# CM_WKUP register map
Vendor: Texas Instruments
Peripheral module from a debugger description file (folder am335x).
Registers are 32-bit, access per field, no defined reset value unless marked. A register's access mark holds for its fields unless they carry their own. Offsets are as the file gives them; lines under a group give offsets from that group; [hi:lo] are bit positions; {n}, {i} and the like mark numbered series; 'fields as' and 'values as' point back to an identical list; <NAME> marks a mode.

## CM_WKUP
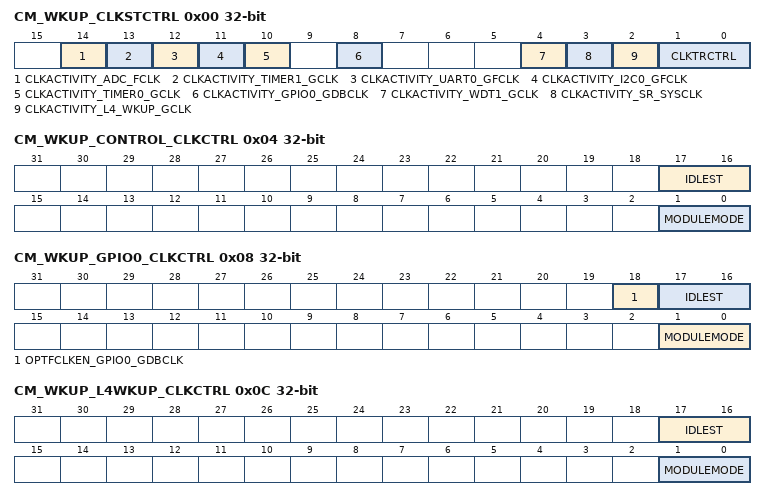
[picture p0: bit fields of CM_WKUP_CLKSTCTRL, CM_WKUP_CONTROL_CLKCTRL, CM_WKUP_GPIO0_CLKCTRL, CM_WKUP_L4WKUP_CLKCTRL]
0x00 CM_WKUP_CLKSTCTRL — This register enables the domain power state transition. It controls the SW supervised clock domain state transition between ON-ACTIVE and ON-INACTIVE states. It also hold one status bit per clock input of the domain.
  [14] CLKACTIVITY_ADC_FCLK ro — This field indicates the state of the ADC clock in the domain.
    0=Inact (Corresponding clock is gated); 1=Act (Corresponding clock is active)
  [13] CLKACTIVITY_TIMER1_GCLK ro — This field indicates the state of the TIMER1 clock in the domain.
    values as CLKACTIVITY_ADC_FCLK
  [12] CLKACTIVITY_UART0_GFCLK ro — This field indicates the state of the UART0 clock in the domain.
    values as CLKACTIVITY_ADC_FCLK
  [11] CLKACTIVITY_I2C0_GFCLK ro — This field indicates the state of the I2C0 clock in the domain.
    values as CLKACTIVITY_ADC_FCLK
  [10] CLKACTIVITY_TIMER0_GCLK ro — This field indicates the state of the WKUPTIMER_GCLK clock in the domain.
    values as CLKACTIVITY_ADC_FCLK
  [8] CLKACTIVITY_GPIO0_GDBCLK ro — This field indicates the state of the WKUPGPIO_DBGICLK clock in the domain.
    values as CLKACTIVITY_ADC_FCLK
  [4] CLKACTIVITY_WDT1_GCLK ro — This field indicates the state of the WDT1_GCLK clock in the domain.
    values as CLKACTIVITY_ADC_FCLK
  [3] CLKACTIVITY_SR_SYSCLK ro — This field indicates the state of the SMARTREFGLEX SYSCLK clock in the domain.
    values as CLKACTIVITY_ADC_FCLK
  [2] CLKACTIVITY_L4_WKUP_GCLK ro — This field indicates the state of the L4_WKUP clock in the domain.
    values as CLKACTIVITY_ADC_FCLK
  [1:0] CLKTRCTRL rw — Controls the clock state transition of the always on clock domain.
    0=NO_SLEEP (NO_SLEEP: Sleep transition cannot be initiated. Wakeup transition may however occur.); 1=SW_SLEEP (SW_SLEEP: Start a software forced sleep transition on the domain.); 2=SW_WKUP (SW_WKUP: Start a software forced wake-up transition on the domain.)
0x04 CM_WKUP_CONTROL_CLKCTRL — This register manages the Control Module clocks.
  [17:16] IDLEST ro — Module idle status.
    0=Func (Module is fully functional, including OCP); 1=Trans (Module is performing transition: wakeup, or sleep, or sleep abortion); 2=Idle (Module is in Idle mode (only OCP part). It is functional if using separate functional clock); 3=Disable (Module is disabled and cannot be accessed)
  [1:0] MODULEMODE rw — Control the way mandatory clocks are managed.
    0=DISABLED (Module is disable by SW. Any OCP access to module results in an error, except if resulting from a module wakeup (asynchronous wakeup).); 2=ENABLE (Module is explicitly enabled. Interface clock (if not used for functions) may be gated according to the clock domain state. Functional clocks are guarantied to stay present. As long as in this configuration, power domain sleep transition cannot happen.)
0x08 CM_WKUP_GPIO0_CLKCTRL — This register manages the GPIO0 clocks.
  [18] OPTFCLKEN_GPIO0_GDBCLK rw — Optional functional clock control.
    0=FCLK_DIS (Optional functional clock is disabled); 1=FCLK_EN (Optional functional clock is enabled)
  [17:16] IDLEST ro — Module idle status.
    values as CM_WKUP_CONTROL_CLKCTRL.IDLEST
  [1:0] MODULEMODE rw — Control the way mandatory clocks are managed.
    values as CM_WKUP_CONTROL_CLKCTRL.MODULEMODE
0x0C CM_WKUP_L4WKUP_CLKCTRL ro — This register manages the L4WKUP clocks.
  [17:16] IDLEST — Module idle status.
    values as CM_WKUP_CONTROL_CLKCTRL.IDLEST
  [1:0] MODULEMODE — Control the way mandatory clocks are managed.
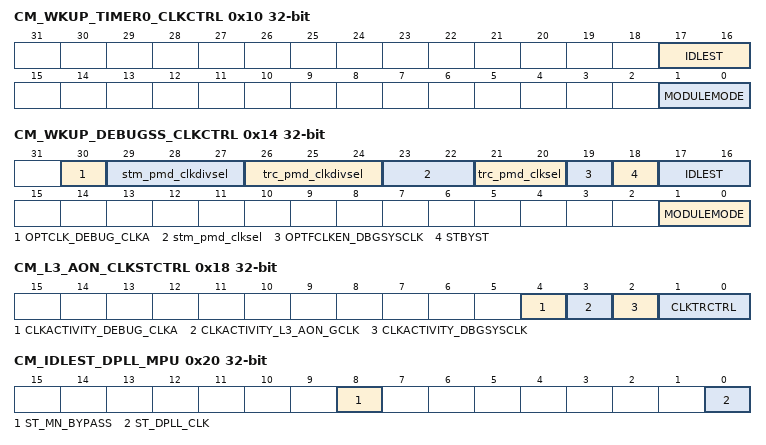
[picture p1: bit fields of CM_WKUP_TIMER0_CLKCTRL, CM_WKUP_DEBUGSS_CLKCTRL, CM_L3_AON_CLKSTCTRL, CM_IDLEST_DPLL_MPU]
0x10 CM_WKUP_TIMER0_CLKCTRL — This register manages the TIMER0 clocks.
  fields as CM_WKUP_CONTROL_CLKCTRL
0x14 CM_WKUP_DEBUGSS_CLKCTRL — This register manages the DEBUGSS clocks.
  [30] OPTCLK_DEBUG_CLKA rw
  [29:27] stm_pmd_clkdivsel rw
  [26:24] trc_pmd_clkdivsel rw
  [23:22] stm_pmd_clksel rw
  [21:20] trc_pmd_clksel rw
  [19] OPTFCLKEN_DBGSYSCLK rw — Optional functional clock control.
    values as CM_WKUP_GPIO0_CLKCTRL.OPTFCLKEN_GPIO0_GDBCLK
  [18] STBYST ro — Module standby status.
    0=Func (Module is functional (not in standby)); 1=Standby (Module is in standby)
  [17:16] IDLEST ro — Module idle status.
    values as CM_WKUP_CONTROL_CLKCTRL.IDLEST
  [1:0] MODULEMODE rw — Control the way mandatory clocks are managed.
    values as CM_WKUP_CONTROL_CLKCTRL.MODULEMODE
0x18 CM_L3_AON_CLKSTCTRL — This register enables the domain power state transition. It controls the SW supervised clock domain state transition between ON-ACTIVE and ON-INACTIVE states. It also hold one status bit per clock input of the domain.
  [4] CLKACTIVITY_DEBUG_CLKA ro — This field indicates the state of the Debugss CLKA clock in the domain.
  [3] CLKACTIVITY_L3_AON_GCLK ro — This field indicates the state of the L3_AON clock in the domain.
    values as CM_WKUP_CLKSTCTRL.CLKACTIVITY_ADC_FCLK
  [2] CLKACTIVITY_DBGSYSCLK ro — This field indicates the state of the Debugss sysclk clock in the domain.
    values as CM_WKUP_CLKSTCTRL.CLKACTIVITY_ADC_FCLK
  [1:0] CLKTRCTRL rw — Controls the clock state transition of the L3 AON clock domain.
    values as CM_WKUP_CLKSTCTRL.CLKTRCTRL
0x1C CM_AUTOIDLE_DPLL_MPU — This register provides automatic control over the DPLL activity.
  [2:0] AUTO_DPLL_MODE rw — This feature is not supported.
0x20 CM_IDLEST_DPLL_MPU ro — This register allows monitoring the master clock activity. This register is read only and automatically updated.[warm reset insensitive]
  [8] ST_MN_BYPASS — DPLL MN_BYPASS status
    0=NO_MNBYPASS (DPLL is not in MN_Bypass); 1=MN_BYPASS (DPLL is in MN_Bypass)
  [0] ST_DPLL_CLK — DPLL clock activity
    0=DPLL_UNLOCKED (DPLL is either in bypass mode or in stop mode.); 1=DPLL_LOCKED (DPLL is LOCKED)
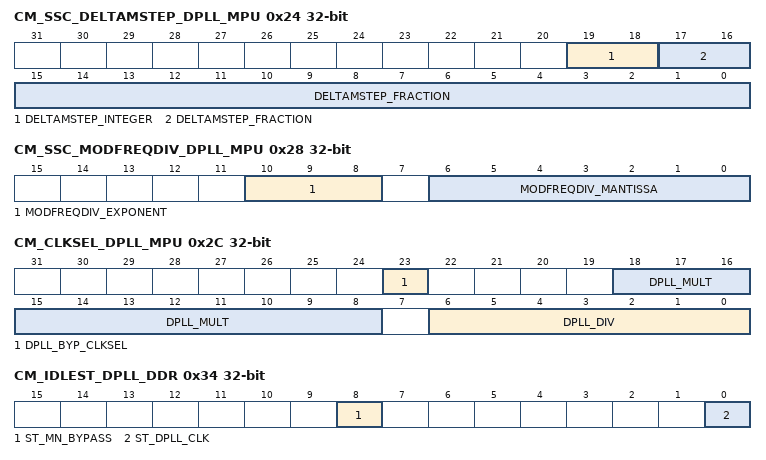
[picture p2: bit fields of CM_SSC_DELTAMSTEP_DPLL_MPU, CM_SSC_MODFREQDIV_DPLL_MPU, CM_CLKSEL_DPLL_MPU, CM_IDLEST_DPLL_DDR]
0x24 CM_SSC_DELTAMSTEP_DPLL_MPU — Control the DeltaMStep parameter for Spread Spectrum Clocking technique DeltaMStep is split into fractional and integer part. [warm reset insensitive]
  [19:18] DELTAMSTEP_INTEGER rw — Integer part for DeltaM coefficient
  [17:0] DELTAMSTEP_FRACTION rw — Fractional part for DeltaM coefficient
0x28 CM_SSC_MODFREQDIV_DPLL_MPU — Control the Modulation Frequency (Fm) for Spread Spectrum Clocking technique by defining it as a ratio of DPLL_REFCLK/4 Fm = [DPLL_REFCLK/4]/MODFREQDIV MODFREQDIV = MODFREQDIV_MANTISSA * 2^MODFREQDIV_EXPONENT [warm reset insensitive]
  [10:8] MODFREQDIV_EXPONENT rw — Set the Exponent component of MODFREQDIV factor
  [6:0] MODFREQDIV_MANTISSA rw — Set the Mantissa component of MODFREQDIV factor
0x2C CM_CLKSEL_DPLL_MPU — This register provides controls over the DPLL.
  [23] DPLL_BYP_CLKSEL rw — Selects CLKINP or CLKINPULOW as Bypass Clock
    0=Sel0 (Selects CLKINP Clock as BYPASS Clock); 1=Sel1 (Selects CLKINPULOW as Bypass Clock)
  [18:8] DPLL_MULT rw — DPLL multiplier factor (2 to 2047). This register is automatically cleared to 0 when the DPLL_EN field in the *CLKMODE_DPLL* register is set to select MN Bypass mode. (equal to input M of DPLL; M=2 to 2047 => DPLL multiplies by M).
  [6:0] DPLL_DIV rw — DPLL divider factor (0 to 127) (equal to input N of DPLL; actual division factor is N+1).
0x30 CM_AUTOIDLE_DPLL_DDR — This register provides automatic control over the DPLL activity.
  [2:0] AUTO_DPLL_MODE rw — AUTO_DPLL_MODE is not supported.
0x34 CM_IDLEST_DPLL_DDR ro — This register allows monitoring the master clock activity. This register is read only and automatically updated. [warm reset insensitive]
  fields as CM_IDLEST_DPLL_MPU
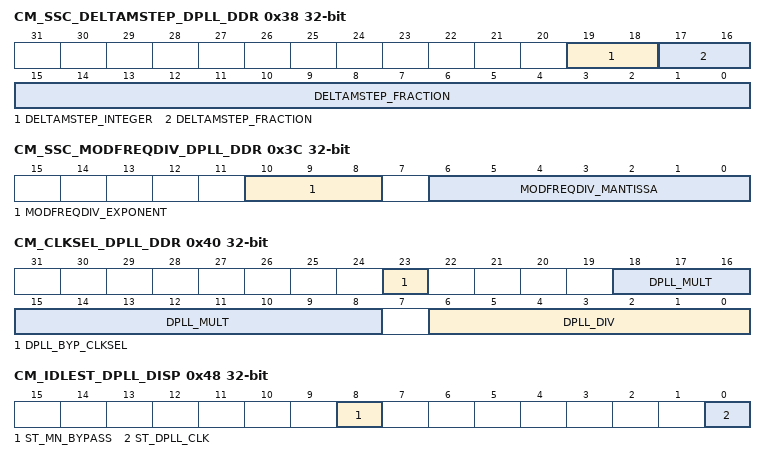
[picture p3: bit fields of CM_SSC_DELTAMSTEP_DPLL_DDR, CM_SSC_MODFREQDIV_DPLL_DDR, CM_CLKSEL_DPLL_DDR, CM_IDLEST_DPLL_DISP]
0x38 CM_SSC_DELTAMSTEP_DPLL_DDR — Control the DeltaMStep parameter for Spread Spectrum Clocking technique DeltaMStep is split into fractional and integer part. [warm reset insensitive]
  [19:18] DELTAMSTEP_INTEGER rw — Integer part for DeltaM coefficient
  [17:0] DELTAMSTEP_FRACTION rw — Fractional setting for DeltaMStep parameter
0x3C CM_SSC_MODFREQDIV_DPLL_DDR — Control the Modulation Frequency (Fm) for Spread Spectrum Clocking technique by defining it as a ratio of DPLL_REFCLK/4 Fm = [DPLL_REFCLK/4]/MODFREQDIV MODFREQDIV = MODFREQDIV_MANTISSA * 2^MODFREQDIV_EXPONENT [warm reset insensitive]
  fields as CM_SSC_MODFREQDIV_DPLL_MPU
0x40 CM_CLKSEL_DPLL_DDR — This register provides controls over the DPLL.
  [23] DPLL_BYP_CLKSEL rw — Select CLKINP orr CLKINPULOW as bypass clock
    values as CM_CLKSEL_DPLL_MPU.DPLL_BYP_CLKSEL
  [18:8] DPLL_MULT rw — DPLL multiplier factor (2 to 2047). This register is automatically cleared to 0 when the DPLL_EN field in the *CLKMODE_DPLL* register is set to select MN Bypass mode. (equal to input M of DPLL; M=2 to 2047 => DPLL multiplies by M).
  [6:0] DPLL_DIV rw — DPLL divider factor (0 to 127) (equal to input N of DPLL; actual division factor is N+1).
0x44 CM_AUTOIDLE_DPLL_DISP — This register provides automatic control over the DPLL activity.
  [2:0] AUTO_DPLL_MODE rw — AUTO_DPLL_MODE is not supported.
0x48 CM_IDLEST_DPLL_DISP ro — This register allows monitoring the master clock activity. This register is read only and automatically updated. [warm reset insensitive]
  fields as CM_IDLEST_DPLL_MPU
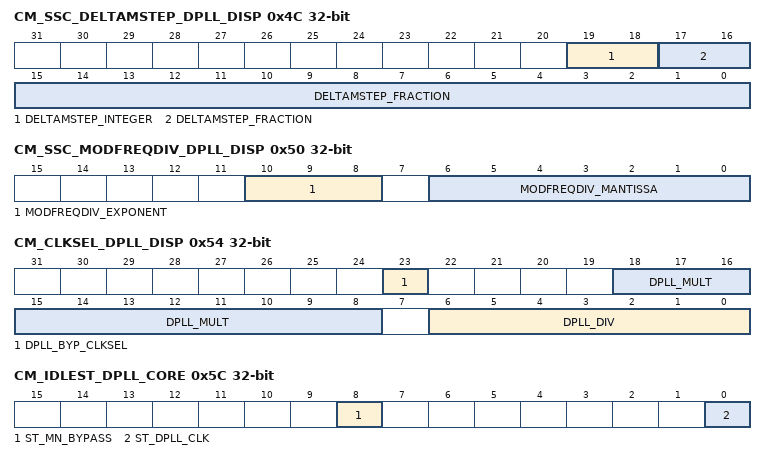
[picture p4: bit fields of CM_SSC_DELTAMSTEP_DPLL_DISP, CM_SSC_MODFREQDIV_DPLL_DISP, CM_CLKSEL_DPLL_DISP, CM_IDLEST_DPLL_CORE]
0x4C CM_SSC_DELTAMSTEP_DPLL_DISP — Control the DeltaMStep parameter for Spread Spectrum Clocking technique DeltaMStep is split into fractional and integer part. [warm reset insensitive]
  fields as CM_SSC_DELTAMSTEP_DPLL_DDR
0x50 CM_SSC_MODFREQDIV_DPLL_DISP — Control the Modulation Frequency (Fm) for Spread Spectrum Clocking technique by defining it as a ratio of DPLL_REFCLK/4 Fm = [DPLL_REFCLK/4]/MODFREQDIV MODFREQDIV = MODFREQDIV_MANTISSA * 2^MODFREQDIV_EXPONENT [warm reset insensitive]
  fields as CM_SSC_MODFREQDIV_DPLL_MPU
0x54 CM_CLKSEL_DPLL_DISP — This register provides controls over the DPLL.
  [23] DPLL_BYP_CLKSEL rw — Select CLKINP or CLKINPULOW as bypass clock
    values as CM_CLKSEL_DPLL_MPU.DPLL_BYP_CLKSEL
  [18:8] DPLL_MULT rw — DPLL multiplier factor (2 to 2047). This register is automatically cleared to 0 when the DPLL_EN field in the *CLKMODE_DPLL* register is set to select MN Bypass mode. (equal to input M of DPLL; M=2 to 2047 => DPLL multiplies by M).
  [6:0] DPLL_DIV rw — DPLL divider factor (0 to 127) (equal to input N of DPLL; actual division factor is N+1).
0x58 CM_AUTOIDLE_DPLL_CORE — This register provides automatic control over the DPLL activity.
  [2:0] AUTO_DPLL_MODE rw — This feature is not supported.
0x5C CM_IDLEST_DPLL_CORE ro — This register allows monitoring the master clock activity. This register is read only and automatically updated. [warm reset insensitive]
  fields as CM_IDLEST_DPLL_MPU
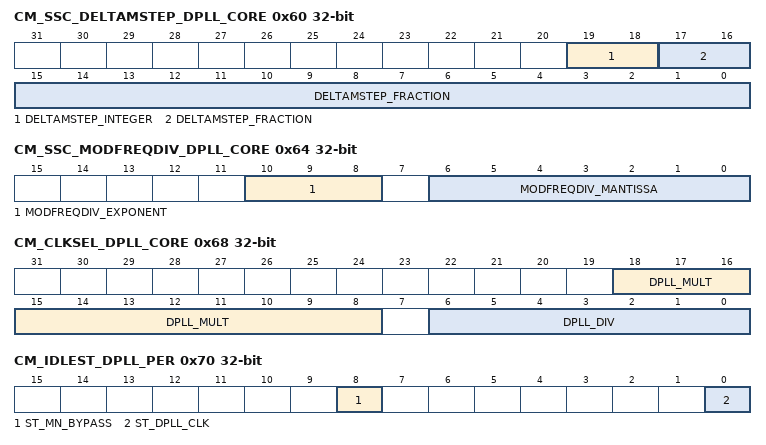
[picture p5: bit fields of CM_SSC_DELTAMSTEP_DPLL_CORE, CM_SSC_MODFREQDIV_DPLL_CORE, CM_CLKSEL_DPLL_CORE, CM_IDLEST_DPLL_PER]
0x60 CM_SSC_DELTAMSTEP_DPLL_CORE — Control the DeltaMStep parameter for Spread Spectrum Clocking technique DeltaMStep is split into fractional and integer part. [warm reset insensitive]
  fields as CM_SSC_DELTAMSTEP_DPLL_DDR
0x64 CM_SSC_MODFREQDIV_DPLL_CORE — Control the Modulation Frequency (Fm) for Spread Spectrum Clocking technique by defining it as a ratio of DPLL_REFCLK/4 Fm = [DPLL_REFCLK/4]/MODFREQDIV MODFREQDIV = MODFREQDIV_MANTISSA * 2^MODFREQDIV_EXPONENT [warm reset insensitive]
  fields as CM_SSC_MODFREQDIV_DPLL_MPU
0x68 CM_CLKSEL_DPLL_CORE — This register provides controls over the DPLL.
  [18:8] DPLL_MULT rw — DPLL multiplier factor (2 to 2047). This register is automatically cleared to 0 when the DPLL_EN field in the *CLKMODE_DPLL* register is set to select MN Bypass mode. (equal to input M of DPLL; M=2 to 2047 => DPLL multiplies by M)
  [6:0] DPLL_DIV rw — DPLL divider factor (0 to 127) (equal to input N of DPLL; actual division factor is N+1).
0x6C CM_AUTOIDLE_DPLL_PER — This register provides automatic control over the DPLL activity.
  [2:0] AUTO_DPLL_MODE rw — AUTO_DPLL_MODE is not supported.
0x70 CM_IDLEST_DPLL_PER ro — This register allows monitoring the master clock activity. This register is read only and automatically updated. [warm reset insensitive]
  fields as CM_IDLEST_DPLL_MPU
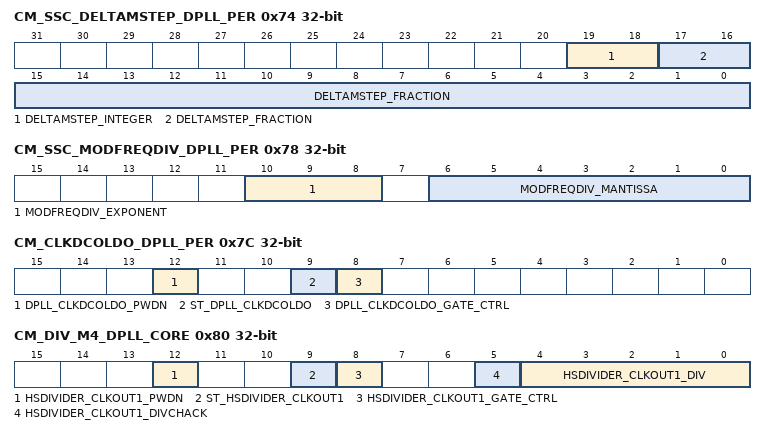
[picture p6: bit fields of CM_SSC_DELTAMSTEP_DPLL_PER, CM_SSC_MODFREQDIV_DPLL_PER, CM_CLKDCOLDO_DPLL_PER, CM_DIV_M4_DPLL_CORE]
0x74 CM_SSC_DELTAMSTEP_DPLL_PER — Control the DeltaMStep parameter for Spread Spectrum Clocking technique DeltaMStep is split into fractional and integer part. [warm reset insensitive]
  fields as CM_SSC_DELTAMSTEP_DPLL_DDR
0x78 CM_SSC_MODFREQDIV_DPLL_PER — Control the Modulation Frequency (Fm) for Spread Spectrum Clocking technique by defining it as a ratio of DPLL_REFCLK/4 Fm = [DPLL_REFCLK/4]/MODFREQDIV MODFREQDIV = MODFREQDIV_MANTISSA * 2^MODFREQDIV_EXPONENT [warm reset insensitive]
  fields as CM_SSC_MODFREQDIV_DPLL_MPU
0x7C CM_CLKDCOLDO_DPLL_PER — This register provides controls over the digitally controlled oscillator output of the PER DPLL.
  [12] DPLL_CLKDCOLDO_PWDN rw — Automatic power down for CLKDCOLDO o/p when it is gated
    0=ALWAYS_ACTIVE (Keep CLKDCOLDO o/p powered on even when it is gated); 1=AUTO_PWDN (Automatically power down CLKDCOLDO o/p when it is gated.)
  [9] ST_DPLL_CLKDCOLDO ro — DPLL CLKDCOLDO status
    0=CLK_ENABLED (The clock output is enabled); 1=CLK_GATED (The clock output is gated)
  [8] DPLL_CLKDCOLDO_GATE_CTRL rw — Control gating of DPLL CLKDCOLDO
    0=CLK_AUTOGATE (Automatically gate this clock when there is no dependency for it); 1=CLK_ENABLE (Force this clock to stay enabled even if there is no request)
0x80 CM_DIV_M4_DPLL_CORE — This register provides controls over the CLKOUT1 o/p of the HSDIVIDER.
  [12] HSDIVIDER_CLKOUT1_PWDN rw — Automatic power down for HSDIVIDER M4 divider and hence CLKOUT1 output when the o/p clock is gated.
    0=ALWAYS_ACTIVE (Keep M4 divider powered on even when CLKOUT1 is gated.); 1=AUTO_PWDN (Automatically power down M4 divider when CLKOUT1 is gated.)
  [9] ST_HSDIVIDER_CLKOUT1 ro — HSDIVIDER CLKOUT1 status
    values as CM_CLKDCOLDO_DPLL_PER.ST_DPLL_CLKDCOLDO
  [8] HSDIVIDER_CLKOUT1_GATE_CTRL rw — Control gating of HSDIVIDER CLKOUT1
    values as CM_CLKDCOLDO_DPLL_PER.DPLL_CLKDCOLDO_GATE_CTRL
  [5] HSDIVIDER_CLKOUT1_DIVCHACK ro — Toggle on this status bit after changing HSDIVIDER_CLKOUT1_DIV indicates that the change in divider value has taken effect
  [4:0] HSDIVIDER_CLKOUT1_DIV rw — DPLL post-divider factor, M4, for internal clock generation. Divide values from 1 to 31.
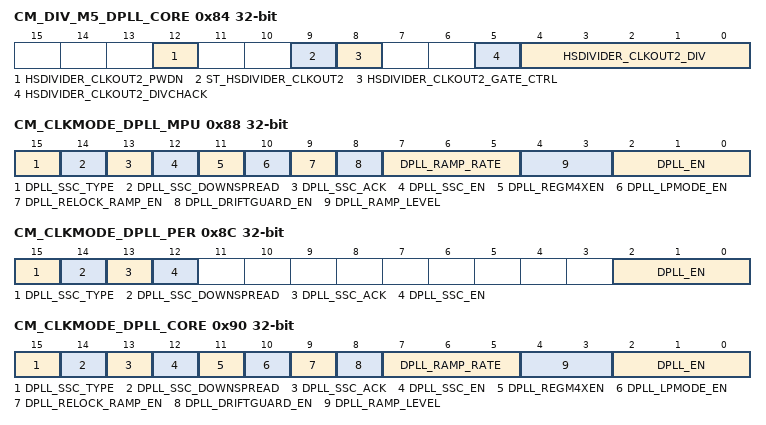
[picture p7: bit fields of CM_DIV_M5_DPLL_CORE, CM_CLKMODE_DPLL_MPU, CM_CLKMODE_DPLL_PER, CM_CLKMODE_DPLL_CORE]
0x84 CM_DIV_M5_DPLL_CORE — This register provides controls over the CLKOUT2 o/p of the HSDIVIDER.
  [12] HSDIVIDER_CLKOUT2_PWDN rw — Automatic power down for HSDIVIDER M5 divider and hence CLKOUT2 output when the o/p clock is gated.
    0=ALWAYS_ACTIVE (Keep M5 divider powered on even when CLKOUT2 is gated.); 1=AUTO_PWDN (Automatically power down M5 divider when CLKOUT2 is gated.)
  [9] ST_HSDIVIDER_CLKOUT2 ro — HSDIVIDER CLKOUT2 status
    values as CM_CLKDCOLDO_DPLL_PER.ST_DPLL_CLKDCOLDO
  [8] HSDIVIDER_CLKOUT2_GATE_CTRL rw — Control gating of HSDIVIDER CLKOUT2
    values as CM_CLKDCOLDO_DPLL_PER.DPLL_CLKDCOLDO_GATE_CTRL
  [5] HSDIVIDER_CLKOUT2_DIVCHACK ro — Toggle on this status bit after changing HSDIVIDER_CLKOUT2_DIV indicates that the change in divider value has taken effect
  [4:0] HSDIVIDER_CLKOUT2_DIV rw — DPLL post-divider factor, M5, for internal clock generation. Divide values from 1 to 31.
0x88 CM_CLKMODE_DPLL_MPU — This register allows controlling the DPLL modes.
  [15] DPLL_SSC_TYPE rw — Select Triangular Spread Spectrum clocking. Always write 0. 0 = Triangular Spread Spectrum Clocking is selected. 1 = Reserved.
  [14] DPLL_SSC_DOWNSPREAD rw — Control if only low frequency spread is required
    0=FULL_SPREAD (When SSC is enabled, clock frequency is spread on both sides of the programmed frequency); 1=LOW_SPREAD (When SSC is enabled, clock frequency is spread only on the lower side of the programmed frequency)
  [13] DPLL_SSC_ACK ro — Acknowledgement from the DPLL regarding start and stop of Spread Spectrum Clocking feature
    0=Disabled (SSC has been turned off on PLL o/ps); 1=Enabled (SSC has been turned on on PLL o/ps)
  [12] DPLL_SSC_EN rw — Enable or disable Spread Spectrum Clocking
    0=Disabled (SSC disabled); 1=Enabled (SSC enabled)
  [11] DPLL_REGM4XEN ro — Enable the REGM4XEN mode of the DPLL. Please check the DPLL documentation to check when this mode can be enabled.
    0=DISABLED (REGM4XEN mode of the DPLL is disabled)
  [10] DPLL_LPMODE_EN rw — Set the DPLL in Low Power mode. Check the DPLL documentation to see when this can be enabled.
    0=DISABLED (Low power mode of the DPLL is disabled); 1=ENABLED (Low power mode of the DPLL is enabled)
  [9] DPLL_RELOCK_RAMP_EN rw — If enabled, the clock ramping feature is used applied during the lock process, as well as the relock process. If disabled, the clock ramping feature is used only during the first lock.
  [8] DPLL_DRIFTGUARD_EN rw — This bit allows to enable or disable the automatic recalibration feature of the DPLL. The DPLL will automatically start a recalibration process upon assertion of the DPLL's RECAL flag if this bit is set.
    0=Diasbled (DRIFTGUARD feature is disabled); 1=Enabled (DRIFTGUARD feature is enabled)
  [7:5] DPLL_RAMP_RATE rw — Selects the time in terms of DPLL REFCLKs spent at each stage of the clock ramping process
    0=REFCLKx2 (2 REFCLKs); 1=REFCLKx4 (4 REFCLKs); 2=REFCLKx8 (8 REFCLKs); 3=REFCLKx16 (16 REFCLKs); 4=REFCLKx32 (32 REFCLKs); 5=REFCLKx64 (64 REFCLKs); 6=REFCLKx128 (128 REFCLKs); 7=REFCLKx512 (512 REFCLKs)
  [4:3] DPLL_RAMP_LEVEL rw — The DPLL provides an output clock frequency ramping feature when switching from bypass clock to normal clock during lock and re-lock. The frequency ramping will happen in a maximum of 4 steps in frequency before the DPLL's frequency lock indicator is asserted. This register is used to enable/disable the DPLL ramping feature. If enabled, it is also used to select the algorithm used for clock ramping
    0=RAMP_DISABLE (CLKOUT => No ramping CLKOUTX2 => No ramping); 1=RAMP_ALGO1 (CLKOUT => Bypass clk -> Fout/8 -> Fout/4 -> Fout/2 -> Fout CLKOUTX2 => Bypass clk -> Foutx2/8 -> Foutx2/4 -> Foutx2/2 -> Foutx2); 2=RAMP_ALGO2 (CLKOUT => Bypass clk -> Fout/4 -> Fout/2 -> Fout/1.5 -> Fout CLKOUTX2 => Bypass clk -> Foutx2/4 -> Foutx2/2 -> Foutx2/1.5 -> Foutx2)
  [2:0] DPLL_EN rw — DPLL control. Upon Warm Reset, the PRCM DPLL control state machine updates this register to reflect MN Bypass mode.
    4=DPLL_MN_BYP_MODE (Put the DPLL in MN Bypass mode. The DPLL_MULT register bits are reset to 0 automatically by putting the DPLL in this mode.); 5=DPLL_LP_BYP_MODE (Put the DPLL in Idle Bypass Low Power mode.); 6=DPLL_FR_BYP_MODE (Put the DPLL in Idle Bypass Fast Relock mode.); 7=DPLL_LOCK_MODE (Enables the DPLL in Lock mode)
0x8C CM_CLKMODE_DPLL_PER — This register allows controlling the DPLL modes.
  [15] DPLL_SSC_TYPE rw — Select Triangular Spread Spectrum clocking. Always write 0. 0 = Triangular Spread Spectrum Clocking is selected. 1 = Reserved.
  [14] DPLL_SSC_DOWNSPREAD rw — Control if only low frequency spread is required
    values as CM_CLKMODE_DPLL_MPU.DPLL_SSC_DOWNSPREAD
  [13] DPLL_SSC_ACK ro — Acknowledgement from the DPLL regarding start and stop of Spread Spectrum Clocking feature
    values as CM_CLKMODE_DPLL_MPU.DPLL_SSC_ACK
  [12] DPLL_SSC_EN rw — Enable or disable Spread Spectrum Clocking
    0=Disabled (SSC disabled); 1=Enabled (SSC enabled)
  [2:0] DPLL_EN rw — DPLL control. Upon Warm Reset, the PRCM DPLL control state machine updates this register to reflect DPLL Low Power Stop mode.
    1=DPLL_LP_STP_MODE (Put the DPLL in Low Power Stop mode); 4=DPLL_MN_BYP_MODE (Put the DPLL in MN Bypass mode. The DPLL_MULT register bits are reset to 0 automatically by putting the DPLL in this mode.); 5=DPLL_LP_BYP_MODE (Put the DPLL in Idle Bypass Low Power mode.); 7=DPLL_LOCK_MODE (Enables the DPLL in Lock mode)
0x90 CM_CLKMODE_DPLL_CORE — This register allows controlling the DPLL modes.
  fields as CM_CLKMODE_DPLL_MPU
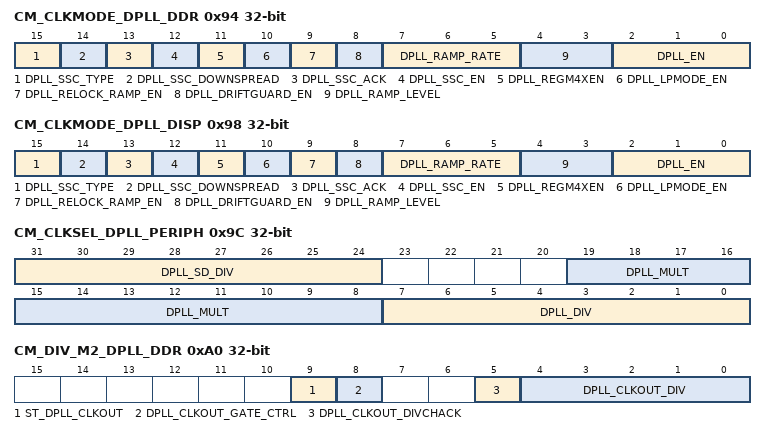
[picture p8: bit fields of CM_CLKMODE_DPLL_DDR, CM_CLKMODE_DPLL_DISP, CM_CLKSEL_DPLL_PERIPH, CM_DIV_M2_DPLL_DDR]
0x94 CM_CLKMODE_DPLL_DDR — This register allows controlling the DPLL modes.
  fields as CM_CLKMODE_DPLL_MPU
0x98 CM_CLKMODE_DPLL_DISP — This register allows controlling the DPLL modes.
  fields as CM_CLKMODE_DPLL_MPU
0x9C CM_CLKSEL_DPLL_PERIPH — This register provides controls over the DPLL.
  [31:24] DPLL_SD_DIV rw — Sigma-Delta divider select (2-255). This factor must be set by s/w to ensure optimum jitter performance. DPLL_SD_DIV = CEILING ([DPLL_MULT/(DPLL_DIV+1)] * CLKINP / 250), where CLKINP is the input clock of the DPLL in MHz). Must be set with M and N factors, and must not be changed once DPLL is locked.
  [19:8] DPLL_MULT rw — DPLL multiplier factor (2 to 4095). This register is automatically cleared to 0 when the DPLL_EN field in the *CLKMODE_DPLL* register is set to select MN Bypass mode. (equal to input M of DPLL; M=2 to 4095 => DPLL multiplies by M).
  [7:0] DPLL_DIV rw — DPLL divider factor (0 to 255) (equal to input N of DPLL; actual division factor is N+1).
0xA0 CM_DIV_M2_DPLL_DDR — This register provides controls over the M2 divider of the DPLL.
  [9] ST_DPLL_CLKOUT ro — DPLL CLKOUT status
    0=CLK_GATED (The clock output is gated); 1=CLK_ENABLED (The clock output is enabled)
  [8] DPLL_CLKOUT_GATE_CTRL rw — Control gating of DPLL CLKOUT
    values as CM_CLKDCOLDO_DPLL_PER.DPLL_CLKDCOLDO_GATE_CTRL
  [5] DPLL_CLKOUT_DIVCHACK ro — Toggle on this status bit after changing DPLL_CLKOUT_DIV indicates that the change in divider value has taken effect
  [4:0] DPLL_CLKOUT_DIV rw — DPLL M2 post-divider factor (1 to 31).
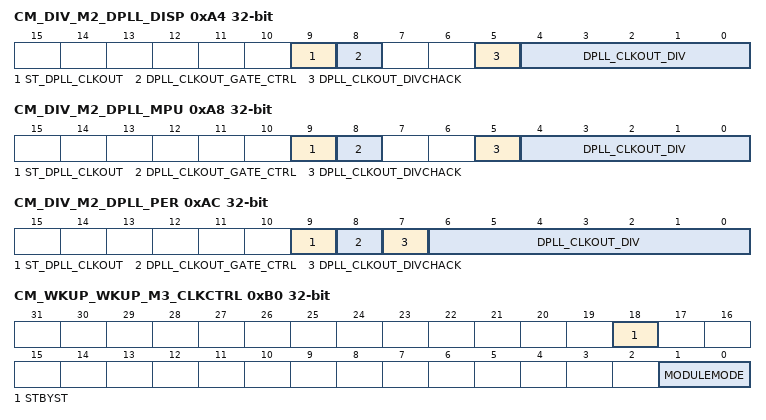
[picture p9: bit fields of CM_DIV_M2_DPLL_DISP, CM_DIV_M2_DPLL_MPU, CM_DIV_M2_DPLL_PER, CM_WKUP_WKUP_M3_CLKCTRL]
0xA4 CM_DIV_M2_DPLL_DISP — This register provides controls over the M2 divider of the DPLL.
  fields as CM_DIV_M2_DPLL_DDR
0xA8 CM_DIV_M2_DPLL_MPU — This register provides controls over the M2 divider of the DPLL.
  fields as CM_DIV_M2_DPLL_DDR
0xAC CM_DIV_M2_DPLL_PER — This register provides controls over the M2 divider of the DPLL.
  [9] ST_DPLL_CLKOUT ro — DPLL CLKOUT status
    values as CM_DIV_M2_DPLL_DDR.ST_DPLL_CLKOUT
  [8] DPLL_CLKOUT_GATE_CTRL rw — Control gating of DPLL CLKOUT
    values as CM_CLKDCOLDO_DPLL_PER.DPLL_CLKDCOLDO_GATE_CTRL
  [7] DPLL_CLKOUT_DIVCHACK ro — Toggle on this status bit after changing DPLL_CLKOUT_DIV indicates that the change in divider value has taken effect
  [6:0] DPLL_CLKOUT_DIV rw — DPLL M2 post-divider factor (1 to 31).
0xB0 CM_WKUP_WKUP_M3_CLKCTRL ro — This register manages the WKUP M3 clocks.
  [18] STBYST — Module standby status.
    values as CM_WKUP_DEBUGSS_CLKCTRL.STBYST
  [1:0] MODULEMODE — Control the way mandatory clocks are managed.
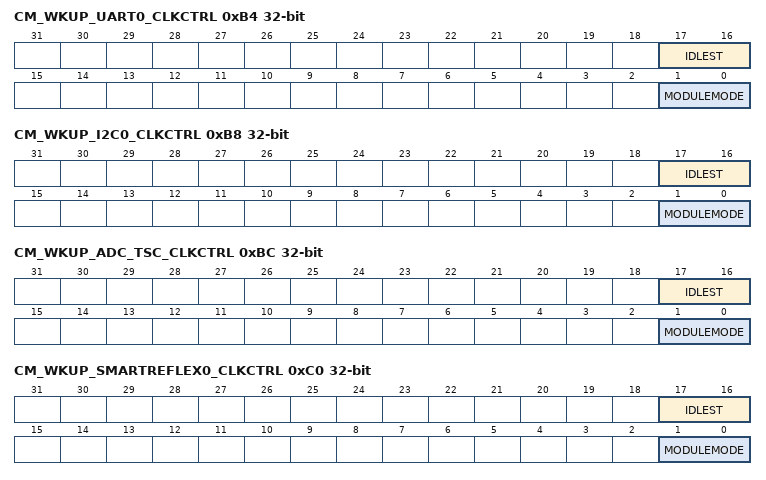
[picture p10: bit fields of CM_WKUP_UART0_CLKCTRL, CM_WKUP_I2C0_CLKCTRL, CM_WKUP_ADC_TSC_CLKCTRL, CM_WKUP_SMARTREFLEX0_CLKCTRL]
0xB4 CM_WKUP_UART0_CLKCTRL — This register manages the UART0 clocks.
  fields as CM_WKUP_CONTROL_CLKCTRL
0xB8 CM_WKUP_I2C0_CLKCTRL — This register manages the I2C0 clocks.
  fields as CM_WKUP_CONTROL_CLKCTRL
0xBC CM_WKUP_ADC_TSC_CLKCTRL — This register manages the ADC clocks.
  fields as CM_WKUP_CONTROL_CLKCTRL
0xC0 CM_WKUP_SMARTREFLEX0_CLKCTRL — This register manages the SmartReflex0 clocks.
  fields as CM_WKUP_CONTROL_CLKCTRL
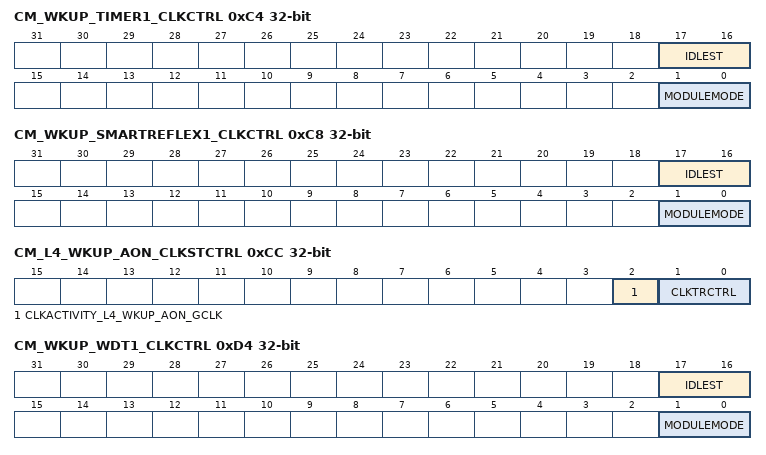
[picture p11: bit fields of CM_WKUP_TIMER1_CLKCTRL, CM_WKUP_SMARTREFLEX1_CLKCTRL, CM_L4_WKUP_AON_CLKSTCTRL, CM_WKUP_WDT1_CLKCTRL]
0xC4 CM_WKUP_TIMER1_CLKCTRL — This register manages the TIMER1 clocks.
  fields as CM_WKUP_CONTROL_CLKCTRL
0xC8 CM_WKUP_SMARTREFLEX1_CLKCTRL — This register manages the SmartReflex1 clocks.
  fields as CM_WKUP_CONTROL_CLKCTRL
0xCC CM_L4_WKUP_AON_CLKSTCTRL — This register enables the domain power state transition. It controls the SW supervised clock domain state transition between ON-ACTIVE and ON-INACTIVE states. It also hold one status bit per clock input of the domain.
  [2] CLKACTIVITY_L4_WKUP_AON_GCLK ro — This field indicates the state of the L4_WKUP clock in the domain.
    values as CM_WKUP_CLKSTCTRL.CLKACTIVITY_ADC_FCLK
  [1:0] CLKTRCTRL rw — Controls the clock state transition of the always on L4 clock domain.
    0=NO_SLEEP (Sleep transition cannot be initiated. Wakeup transition may however occur.); 1=SW_SLEEP (Start a software forced sleep transition on the domain.); 2=SW_WKUP (Start a software forced wake-up transition on the domain.)
0xD4 CM_WKUP_WDT1_CLKCTRL — This register manages the WDT1 clocks.
  fields as CM_WKUP_CONTROL_CLKCTRL
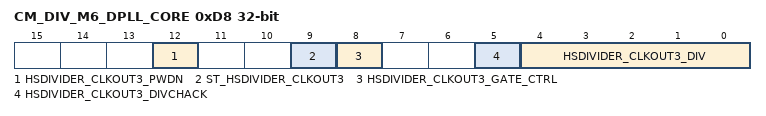
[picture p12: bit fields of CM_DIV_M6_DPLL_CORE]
0xD8 CM_DIV_M6_DPLL_CORE — This register provides controls over the CLKOUT3 o/p of the HSDIVIDER. [warm reset insensitive]
  [12] HSDIVIDER_CLKOUT3_PWDN rw — Automatic power down for HSDIVIDER M6 divider and hence CLKOUT3 output when the o/p clock is gated.
    0=ALWAYS_ACTIVE (Keep M6 divider powered on even when CLKOUT3 is gated.); 1=AUTO_PWDN (Automatically power down M6 divider when CLKOUT3 is gated.)
  [9] ST_HSDIVIDER_CLKOUT3 ro — HSDIVIDER CLKOUT3 status
    values as CM_CLKDCOLDO_DPLL_PER.ST_DPLL_CLKDCOLDO
  [8] HSDIVIDER_CLKOUT3_GATE_CTRL rw — Control gating of HSDIVIDER CLKOUT3
    values as CM_CLKDCOLDO_DPLL_PER.DPLL_CLKDCOLDO_GATE_CTRL
  [5] HSDIVIDER_CLKOUT3_DIVCHACK ro — Toggle on this status bit after changing HSDIVIDER_CLKOUT3_DIV indicates that the change in divider value has taken effect
  [4:0] HSDIVIDER_CLKOUT3_DIV rw — DPLL post-divider factor, M6, for internal clock generation. Divide values from 1 to 31.
